VERSION ""

NS_ :

BS_:

BU_: VCU GrayHill

BO_ 2565799921 GrayHill_ACL: 8 Vector__XXX

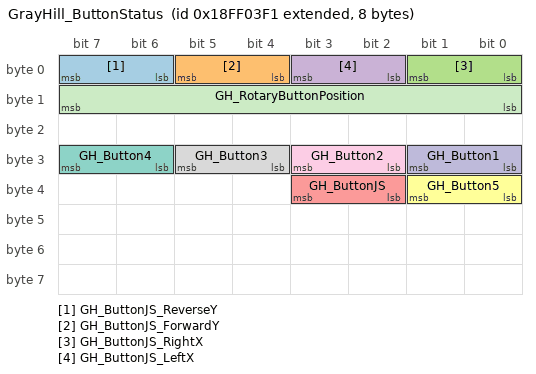
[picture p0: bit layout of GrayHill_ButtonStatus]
BO_ 2566849521 GrayHill_ButtonStatus: 8 GrayHill
 SG_ GH_ButtonJS_ReverseY : 6|2@1+ (1,0) [0|3] "" Vector__XXX
 SG_ GH_ButtonJS_ForwardY : 4|2@1+ (1,0) [0|3] "" Vector__XXX
 SG_ GH_ButtonJS_RightX : 0|2@1+ (1,0) [0|3] "" Vector__XXX
 SG_ GH_ButtonJS_LeftX : 2|2@1+ (1,0) [0|3] "" Vector__XXX
 SG_ GH_ButtonJS : 34|2@1+ (1,0) [0|3] "" Vector__XXX
 SG_ GH_Button5 : 32|2@1+ (1,0) [0|3] "" Vector__XXX
 SG_ GH_Button4 : 30|2@1+ (1,0) [0|3] "" Vector__XXX
 SG_ GH_Button3 : 28|2@1+ (1,0) [0|3] "" Vector__XXX
 SG_ GH_Button2 : 26|2@1+ (1,0) [0|3] "" Vector__XXX
 SG_ GH_Button1 : 24|2@1+ (1,0) [0|3] "" Vector__XXX
 SG_ GH_RotaryButtonPosition : 8|8@1+ (1,0) [0|255] "" Vector__XXX

BA_DEF_ BU_  "NmStationAddress" HEX 0 0;
BA_DEF_ BO_  "GenMsgCycleTime" INT 0 0;
BA_DEF_ BO_  "GenMsgSendType" ENUM  "Cyclic","not_used","not_used","not_used","not_used","Cyclic","not_used","IfActive";
BA_DEF_DEF_  "NmStationAddress" 0;
BA_DEF_DEF_  "GenMsgCycleTime" 0;
BA_DEF_DEF_  "GenMsgSendType" "not_used";
BA_ "NmStationAddress" BU_ VCU 97;
BA_ "NmStationAddress" BU_ GrayHill 241;
BA_ "GenMsgSendType" BO_ 2566849521 0;
BA_ "GenMsgCycleTime" BO_ 2566849521 100;
